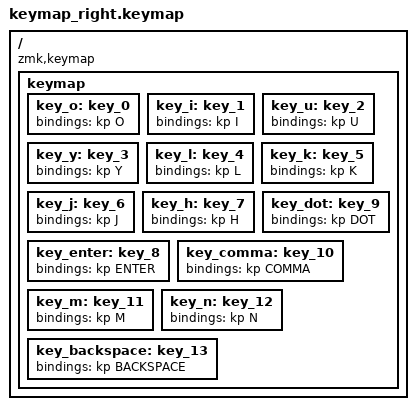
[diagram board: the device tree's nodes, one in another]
/ { compatible = "zmk,keymap"; keymap {
        key_o: key_0 { bindings = <&kp O>; };
        key_i: key_1 { bindings = <&kp I>; };
        key_u: key_2 { bindings = <&kp U>; };
        key_y: key_3 { bindings = <&kp Y>; };
        key_l: key_4 { bindings = <&kp L>; };
        key_k: key_5 { bindings = <&kp K>; };
        key_j: key_6 { bindings = <&kp J>; };
        key_h: key_7 { bindings = <&kp H>; };
        key_enter: key_8 { bindings = <&kp ENTER>; };
        key_dot: key_9 { bindings = <&kp DOT>; };
        key_comma: key_10 { bindings = <&kp COMMA>; };
        key_m: key_11 { bindings = <&kp M>; };
        key_n: key_12 { bindings = <&kp N>; };
        key_backspace: key_13 { bindings = <&kp BACKSPACE>; };
    };
};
